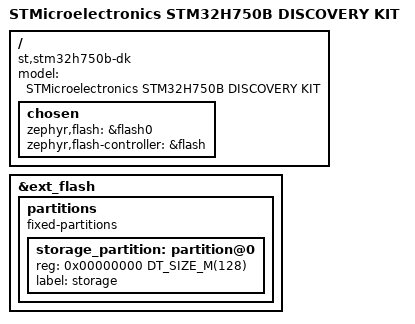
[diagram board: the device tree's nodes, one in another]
/*
 * Copyright (c) 2023-2024 STMicroelectronics
 *
 * SPDX-License-Identifier: Apache-2.0
 */

/dts-v1/;
#include "stm32h750b_dk-common.dtsi"

/ {
	compatible = "st,stm32h750b-dk";
	model = "STMicroelectronics STM32H750B DISCOVERY KIT";

	chosen {
		zephyr,flash = &flash0;
		zephyr,flash-controller = &flash;
	};
};

&ext_flash {
	status = "okay";

	partitions {
		compatible = "fixed-partitions";
		#address-cells = <1>;
		#size-cells = <1>;

		storage_partition: partition@0 {
			reg = <0x00000000 DT_SIZE_M(128)>; /* 128MB */
			label = "storage";
		};
	};
};
